# ATSAMA5D34 register map
Vendor: Microchip Technology; Series: SAMA5D3; File version: 0
Registers are 32-bit, read-write, reset 0x0 unless marked. A register's access mark holds for its fields unless they carry their own. Offsets are from the block's base; [hi:lo] are bit positions; {n}, {i} and the like mark numbered series; 'fields as' and 'values as' point back to an identical list.

## PMC — Power Management Controller
Base 0xFFFFFC00
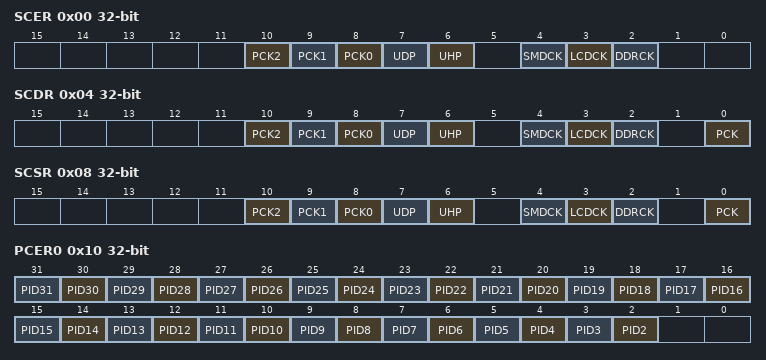
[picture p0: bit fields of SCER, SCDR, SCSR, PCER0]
0x00 SCER wo — System Clock Enable Register
  [10] PCK2 — Programmable Clock 2 Output Enable
  [9] PCK1 — Programmable Clock 1 Output Enable
  [8] PCK0 — Programmable Clock 0 Output Enable
  [7] UDP — USB Device Clock Enable
  [6] UHP — USB Host OHCI Clocks Enable
  [4] SMDCK — SMD Clock Enable
  [3] LCDCK — MCK2x Clock Enable
  [2] DDRCK — DDR Clock Enable
0x04 SCDR wo — System Clock Disable Register
  [10] PCK2 — Programmable Clock 2 Output Disable
  [9] PCK1 — Programmable Clock 1 Output Disable
  [8] PCK0 — Programmable Clock 0 Output Disable
  [7] UDP — USB Device Clock Enable
  [6] UHP — USB Host OHCI Clock Disable
  [4] SMDCK — SMD Clock Disable
  [3] LCDCK — MCK2x Clock Disable
  [2] DDRCK — DDR Clock Disable
  [0] PCK — Processor Clock Disable
0x08 SCSR ro — System Clock Status Register
  [10] PCK2 — Programmable Clock 2 Output Status
  [9] PCK1 — Programmable Clock 1 Output Status
  [8] PCK0 — Programmable Clock 0 Output Status
  [7] UDP — USB Device Port Clock Status
  [6] UHP — USB Host Port Clock Status
  [4] SMDCK — SMD Clock Status
  [3] LCDCK — MCK2x Clock Status
  [2] DDRCK — DDR Clock Status
  [0] PCK — Processor Clock Status
0x10 PCER0 wo — Peripheral Clock Enable Register 0
  [n] PID{n} (n=2..31) — Peripheral Clock {n} Enable
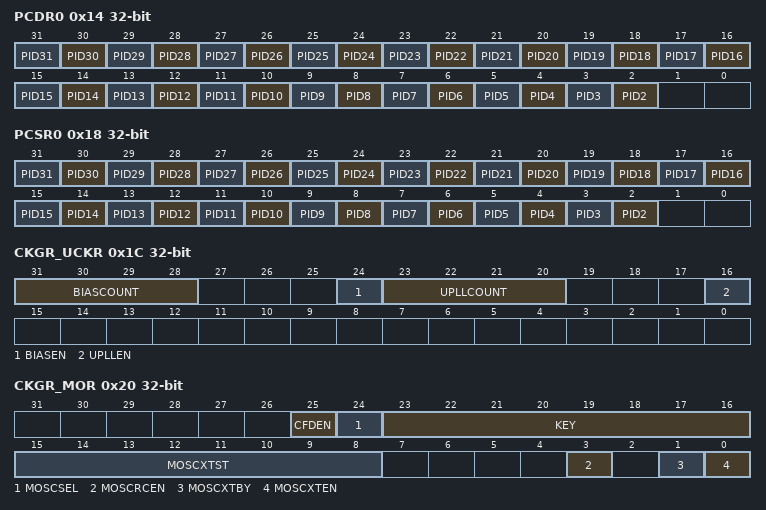
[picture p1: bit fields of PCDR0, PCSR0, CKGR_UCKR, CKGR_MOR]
0x14 PCDR0 wo — Peripheral Clock Disable Register 0
  [n] PID{n} (n=2..31) — Peripheral Clock {n} Disable
0x18 PCSR0 ro — Peripheral Clock Status Register 0
  [n] PID{n} (n=2..31) — Peripheral Clock {n} Status
0x1C CKGR_UCKR — UTMI Clock Register
  [31:28] BIASCOUNT — UTMI BIAS Start-up Time
  [24] BIASEN — UTMI BIAS Enable
  [23:20] UPLLCOUNT — UTMI PLL Start-up Time
  [16] UPLLEN — UTMI PLL Enable
0x20 CKGR_MOR — Main Oscillator Register
  [25] CFDEN — Clock Failure Detector Enable
  [24] MOSCSEL — Main Clock Oscillator Selection
  [23:16] KEY — Password
    55=PASSWD (Writing any other value in this field aborts the write operation.)
  [15:8] MOSCXTST — 8 to 48 MHz Crystal Oscillator Startup Time
  [3] MOSCRCEN — 12 MHz RC Oscillator Enable
  [1] MOSCXTBY — 8 to 48 MHz Crystal Oscillator Bypass
  [0] MOSCXTEN — 8 to 48 MHz Crystal Oscillator Enable
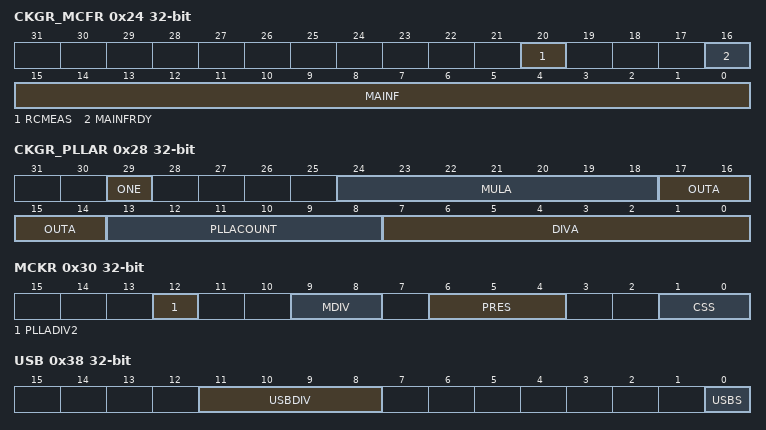
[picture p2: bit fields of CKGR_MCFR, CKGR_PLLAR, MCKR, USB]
0x24 CKGR_MCFR — Main Clock Frequency Register
  [20] RCMEAS — RC Oscillator Frequency Measure (write-only)
  [16] MAINFRDY — Main Clock Frequency Measure Ready
  [15:0] MAINF — Main Clock Frequency
0x28 CKGR_PLLAR — PLLA Register
  [29] ONE — Must Be Set to 1
  [24:18] MULA — PLLA Multiplier
  [17:14] OUTA — PLLA Clock Frequency Range
  [13:8] PLLACOUNT — PLLA Counter
  [7:0] DIVA — Divider A
    0=Divider output is 0; 1=BYPASS (Divider is bypassed)
0x30 MCKR — Master Clock Register
  [12] PLLADIV2 — PLLA Divisor by 2
  [9:8] MDIV — Master Clock Division
    0=EQ_PCK (Master Clock is Prescaler Output Clock divided by 1.Warning: DDRCK is not available.); 1=PCK_DIV2 (Master Clock is Prescaler Output Clock divided by 2. DDRCK is equal to MCK.); 2=PCK_DIV4 (Master Clock is Prescaler Output Clock divided by 4. DDRCK is equal to MCK.); 3=PCK_DIV3 (Master Clock is Prescaler Output Clock divided by 3. DDRCK is equal to MCK.)
  [6:4] PRES — Master/Processor Clock Prescaler
    0=CLOCK (Selected clock); 1=CLOCK_DIV2 (Selected clock divided by 2); 2=CLOCK_DIV4 (Selected clock divided by 4); 3=CLOCK_DIV8 (Selected clock divided by 8); 4=CLOCK_DIV16 (Selected clock divided by 16); 5=CLOCK_DIV32 (Selected clock divided by 32); 6=CLOCK_DIV64 (Selected clock divided by 64)
  [1:0] CSS — Master/Processor Clock Source Selection
    0=SLOW_CLK (Slow clock is selected); 1=MAIN_CLK (Main clock is selected); 2=PLLA_CLK (PLLACK/2 is selected if PLLADIV2 = 1PLLACK is selected if PLLADIV2 = 0); 3=UPLL_CLK (UPLL Clock is selected)
0x38 USB — USB Clock Register
  [11:8] USBDIV — Divider for USB OHCI Clock
  [0] USBS — USB OHCI Input Clock Selection
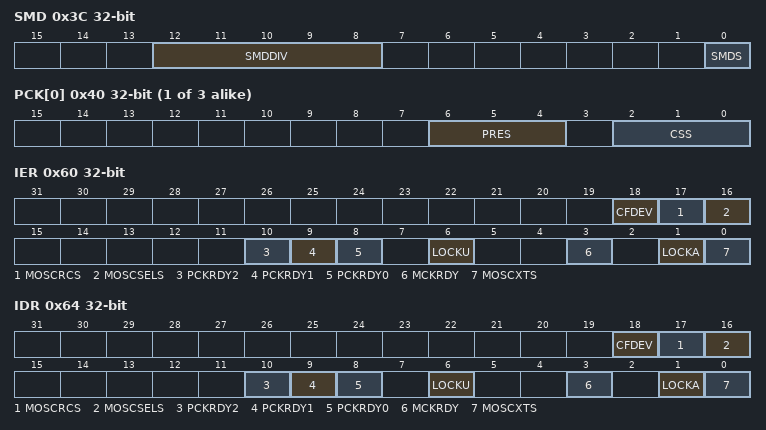
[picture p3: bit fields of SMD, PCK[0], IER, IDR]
0x3C SMD — Soft Modem Clock Register
  [12:8] SMDDIV — Divider for SMD Clock
  [0] SMDS — SMD Input Clock Selection
{0x40+4i} PCK[{i}] (i=0..2) — Programmable Clock 0 Register
  [6:4] PRES — Programmable Clock Prescaler
    values as MCKR.PRES
  [2:0] CSS — Master Clock Source Selection
    0=SLOW_CLK (Slow clock is selected); 1=MAIN_CLK (Main clock is selected); 2=PLLA_CLK (PLLACK is selected); 3=UPLL_CLK (UPLL Clock is selected); 4=MCK_CLK (Master Clock is selected)
0x60 IER wo — Interrupt Enable Register
  [18] CFDEV — Clock Failure Detector Event Interrupt Enable
  [17] MOSCRCS — 12 MHz RC Oscillator Status Interrupt Enable
  [16] MOSCSELS — Main Clock Source Oscillator Selection Status Interrupt Enable
  [10] PCKRDY2 — Programmable Clock Ready 2 Interrupt Enable
  [9] PCKRDY1 — Programmable Clock Ready 1 Interrupt Enable
  [8] PCKRDY0 — Programmable Clock Ready 0 Interrupt Enable
  [6] LOCKU — UTMI PLL Lock Interrupt Enable
  [3] MCKRDY — Master Clock Ready Interrupt Enable
  [1] LOCKA — PLLA Lock Interrupt Enable
  [0] MOSCXTS — 8 to 48 MHz Crystal Oscillator Status Interrupt Enable
0x64 IDR wo — Interrupt Disable Register
  [18] CFDEV — Clock Failure Detector Event Interrupt Disable
  [17] MOSCRCS — 12 MHz RC Oscillator Status Interrupt Disable
  [16] MOSCSELS — Main Oscillator Clock Source Selection Status Interrupt Disable
  [10] PCKRDY2 — Programmable Clock Ready 2 Interrupt Disable
  [9] PCKRDY1 — Programmable Clock Ready 1 Interrupt Disable
  [8] PCKRDY0 — Programmable Clock Ready 0 Interrupt Disable
  [6] LOCKU — UTMI PLL Lock Interrupt Enable
  [3] MCKRDY — Master Clock Ready Interrupt Disable
  [1] LOCKA — PLLA Lock Interrupt Disable
  [0] MOSCXTS — 8 to 48 MHz Crystal Oscillator Status Interrupt Disable
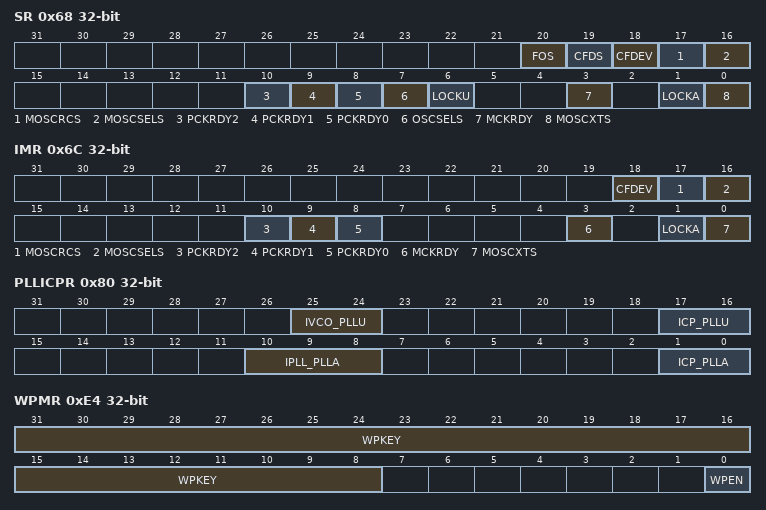
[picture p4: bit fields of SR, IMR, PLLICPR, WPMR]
0x68 SR ro — Status Register
  [20] FOS — Clock Failure Detector Fault Output Status
  [19] CFDS — Clock Failure Detector Status
  [18] CFDEV — Clock Failure Detector Event
  [17] MOSCRCS — 12 MHz RC Oscillator Status
  [16] MOSCSELS — Main Oscillator Selection Status
  [10] PCKRDY2 — Programmable Clock Ready Status
  [9] PCKRDY1 — Programmable Clock Ready Status
  [8] PCKRDY0 — Programmable Clock Ready Status
  [7] OSCSELS — Slow Clock Oscillator Selection
  [6] LOCKU — UPLL Clock Status
  [3] MCKRDY — Master Clock Status
  [1] LOCKA — PLLA Lock Status
  [0] MOSCXTS — 8 to 48 MHz Crystal Oscillator Status
0x6C IMR ro — Interrupt Mask Register
  [18] CFDEV — Clock Failure Detector Event Interrupt Mask
  [17] MOSCRCS — 12 MHz RC Oscillator Status Interrupt Mask
  [16] MOSCSELS — Main Oscillator Clock Source Selection Status Interrupt Mask
  [10] PCKRDY2 — Programmable Clock Ready 2 Interrupt Mask
  [9] PCKRDY1 — Programmable Clock Ready 1 Interrupt Mask
  [8] PCKRDY0 — Programmable Clock Ready 0 Interrupt Mask
  [3] MCKRDY — Master Clock Ready Interrupt Mask
  [1] LOCKA — PLLA Lock Interrupt Mask
  [0] MOSCXTS — 8 to 48 MHz Crystal Oscillator Status Interrupt Mask
0x78 FOCR wo — Fault Output Clear Register
  [0] FOCLR — Fault Output Clear
0x80 PLLICPR — PLL Charge Pump Current Register
  [25:24] IVCO_PLLU — Voltage Control Output Current PLL UTMI
  [17:16] ICP_PLLU — Charge Pump Current PLL UTMI
  [10:8] IPLL_PLLA — Engineering Configuration PLLA
  [1:0] ICP_PLLA — Must Be Written to Zero
0xE4 WPMR — Write ProtectIon Mode Register
  [31:8] WPKEY — Write Protection Key
    0x504D43=PASSWD (Writing any other value in this field aborts the write operation of the WPEN bit.Always reads as 0.)
  [0] WPEN — Write Protection Enable
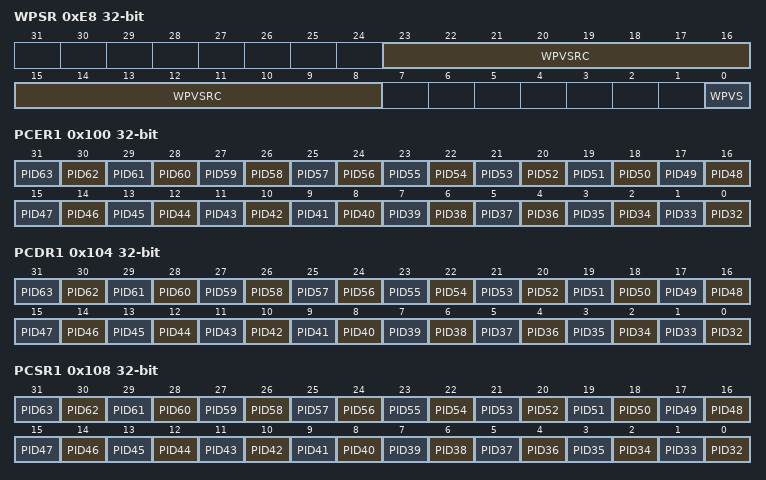
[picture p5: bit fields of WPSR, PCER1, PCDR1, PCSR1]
0xE8 WPSR ro — Write Protection Status Register
  [23:8] WPVSRC — Write Protection Violation Source
  [0] WPVS — Write Protection Violation Status
0x100 PCER1 wo — Peripheral Clock Enable Register 1
  [n-32] PID{n} (n=32..63) — Peripheral Clock {n} Enable
0x104 PCDR1 wo — Peripheral Clock Disable Register 1
  [n-32] PID{n} (n=32..63) — Peripheral Clock {n} Disable
0x108 PCSR1 ro — Peripheral Clock Status Register 1
  [n-32] PID{n} (n=32..63) — Peripheral Clock {n} Status
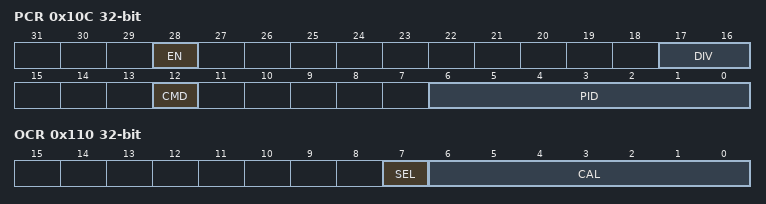
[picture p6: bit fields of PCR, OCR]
0x10C PCR — Peripheral Control Register
  [28] EN — Enable
  [17:16] DIV — Divisor Value
    0=PERIPH_DIV_MCK (Peripheral clock is MCK); 1=PERIPH_DIV2_MCK (Peripheral clock is MCK/2); 2=PERIPH_DIV4_MCK (Peripheral clock is MCK/4); 3=PERIPH_DIV8_MCK (Peripheral clock is MCK/8)
  [12] CMD — Command
  [6:0] PID — Peripheral ID
0x110 OCR — Oscillator Calibration Register
  [7] SEL — Selection of RC Oscillator Calibration Bits
  [6:0] CAL — 12 MHz RC Oscillator Calibration Bits
